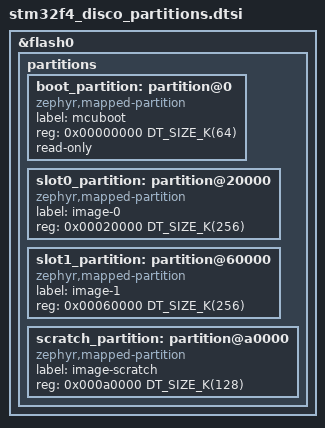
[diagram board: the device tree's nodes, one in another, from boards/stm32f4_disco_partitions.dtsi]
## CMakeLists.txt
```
# SPDX-License-Identifier: Apache-2.0

cmake_minimum_required(VERSION 3.20.0)

find_package(Zephyr REQUIRED HINTS $ENV{ZEPHYR_BASE})
project(mcumgr_update)

target_sources(app PRIVATE src/main.c)
```

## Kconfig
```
# SPDX-License-Identifier: Apache-2.0

mainmenu "MCUmgr update test application"

config APP_BLINK_MS
	int "LED blink half-period in ms"
	default 1000
	help
	  Each test image uses a different blink rate, so the running
	  version is visible on the board.

config APP_SIMULATE_BAD_IMAGE
	bool "Simulate a broken image (never confirm)"
	help
	  The self-test fails, so the image is never confirmed.
	  SWUpdate times out waiting for the confirmation, resets the MCU
	  and MCUboot reverts to the previous image.

source "Kconfig.zephyr"
```

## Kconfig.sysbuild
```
# SPDX-License-Identifier: Apache-2.0

# MCUboot mode per board. Both modes keep the rollback (test / confirm):
# - frdm_k64f: 4 KiB sectors, equal slots -> swap using move
# - stm32f4_disco: 128 KiB sectors -> swap using scratch, as the other
#   STM32F4 boards of Zephyr
choice MCUBOOT_MODE
	default MCUBOOT_MODE_SWAP_SCRATCH if "$(BOARD)" = "stm32f4_disco"
	default MCUBOOT_MODE_SWAP_USING_MOVE if "$(BOARD)" = "frdm_k64f"
endchoice

source "share/sysbuild/Kconfig"
```

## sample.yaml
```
sample:
  name: MCUmgr update test (SWUpdate mcumgr handler)
  description: Signed MCUboot application updated over SMP/UART by SWUpdate
common:
  sysbuild: true
  # no console output: tested with SWUpdate on the host, see README.md
  build_only: true
  platform_allow:
    - frdm_k64f
    - stm32f4_disco
  integration_platforms:
    - frdm_k64f
    - stm32f4_disco
  tags: mcumgr mcuboot dfu
tests:
  sample.mcumgr_update.v1: {}
  sample.mcumgr_update.v2:
    extra_args: EXTRA_CONF_FILE="v2.conf"
  sample.mcumgr_update.bad:
    extra_args: EXTRA_CONF_FILE="bad.conf"
```

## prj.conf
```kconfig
# GPIO for the status LED
CONFIG_GPIO=y

# MCUmgr core
CONFIG_NET_BUF=y
CONFIG_ZCBOR=y
CONFIG_CRC=y
CONFIG_BASE64=y
CONFIG_MCUMGR=y
CONFIG_SYSTEM_WORKQUEUE_STACK_SIZE=2304
CONFIG_MAIN_STACK_SIZE=2176

# Image management (upload, test, confirm) and OS group (reset)
CONFIG_FLASH=y
CONFIG_FLASH_MAP=y
CONFIG_STREAM_FLASH=y
CONFIG_IMG_MANAGER=y
CONFIG_MCUMGR_GRP_IMG=y
CONFIG_MCUMGR_GRP_OS=y

# Build an MCUboot compatible, signed image
CONFIG_BOOTLOADER_MCUBOOT=y

# SMP on its own UART transport, on the UART in zephyr,uart-mcumgr (board
# devicetree or boards/<board>.overlay). This UART carries only SMP frames:
# no shell, no console, no printk (MCUboot still prints its boot log, the
# host ignores it).
CONFIG_CONSOLE=y
CONFIG_UART_CONSOLE=n
CONFIG_PRINTK=n
CONFIG_BOOT_BANNER=n
CONFIG_LOG=n
CONFIG_SHELL=n
CONFIG_UART_MCUMGR=y
CONFIG_MCUMGR_TRANSPORT_UART=y
```

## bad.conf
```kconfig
# Broken image: boots but never confirms -> rollback test
CONFIG_APP_BLINK_MS=50
CONFIG_APP_SIMULATE_BAD_IMAGE=y
CONFIG_MCUBOOT_IMGTOOL_SIGN_VERSION="3.0.0+0"
```

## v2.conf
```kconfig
# Second image: fast blink, higher MCUboot version
CONFIG_APP_BLINK_MS=150
CONFIG_MCUBOOT_IMGTOOL_SIGN_VERSION="2.0.0+0"
```

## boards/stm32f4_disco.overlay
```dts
/*
 * SPDX-License-Identifier: Apache-2.0
 *
 * STM32F4DISCOVERY (STM32F407G-DISC1) + MikroElektronika STM32F4 Discovery
 * Shield (MIKROE-1481).
 *
 * SMP runs on USART2 (PA2 TX, PA3 RX), wired on the shield to its FT232RL
 * USB-UART (mini-B connector, /dev/ttyUSB0 on the host). The application
 * has no console: USART2 carries only SMP frames (and the MCUboot log).
 */

#include "stm32f4_disco_partitions.dtsi"

/ {
	chosen {
		zephyr,code-partition = &slot0_partition;
		zephyr,uart-mcumgr = &usart2;
	};
};
```

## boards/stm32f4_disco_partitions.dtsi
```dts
/*
 * SPDX-License-Identifier: Apache-2.0
 *
 * MCUboot flash layout for the STM32F407VG (1 MiB) of the STM32F4DISCOVERY,
 * used by the application and by MCUboot (see sysbuild.cmake).
 *
 * Sectors: 4 x 16 KiB, 1 x 64 KiB, 7 x 128 KiB. Both slots and the scratch
 * area are made of 128 KiB sectors (swap using scratch).
 *
 * zephyr,mapped-partition (Zephyr 4.4+): a fixed-partitions code partition
 * is deprecated.
 */

&flash0 {
	partitions {
		#address-cells = <1>;
		#size-cells = <1>;
		ranges;

		/* sectors 0-3 */
		boot_partition: partition@0 {
			compatible = "zephyr,mapped-partition";
			label = "mcuboot";
			reg = <0x00000000 DT_SIZE_K(64)>;
			read-only;
		};

		/* sector 4 (64 KiB) unused */

		/* sectors 5-6 */
		slot0_partition: partition@20000 {
			compatible = "zephyr,mapped-partition";
			label = "image-0";
			reg = <0x00020000 DT_SIZE_K(256)>;
		};

		/* sectors 7-8 */
		slot1_partition: partition@60000 {
			compatible = "zephyr,mapped-partition";
			label = "image-1";
			reg = <0x00060000 DT_SIZE_K(256)>;
		};

		/* sector 9 */
		scratch_partition: partition@a0000 {
			compatible = "zephyr,mapped-partition";
			label = "image-scratch";
			reg = <0x000a0000 DT_SIZE_K(128)>;
		};
	};
};
```

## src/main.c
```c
/*
 * SPDX-License-Identifier: Apache-2.0
 *
 * Test application for the SWUpdate "mcumgr" handler.
 *
 * - Exposes MCUmgr SMP (image + os groups) on the dedicated UART
 *   transport (uart0). The UART carries only SMP frames: no console,
 *   no shell, no printk.
 * - At boot, if MCUboot started this image in test mode, it runs a
 *   self-test and confirms the image. With CONFIG_APP_SIMULATE_BAD_IMAGE
 *   the self-test fails, the image is never confirmed and MCUboot
 *   reverts it at the next reset.
 * - The LED blink rate identifies the running build; the version is also
 *   reported by SMP (image state "version").
 */

#include <errno.h>
#include <zephyr/kernel.h>
#include <zephyr/drivers/gpio.h>
#include <zephyr/dfu/mcuboot.h>

static const struct gpio_dt_spec led = GPIO_DT_SPEC_GET(DT_ALIAS(led0), gpios);

static int self_test(void)
{
	if (IS_ENABLED(CONFIG_APP_SIMULATE_BAD_IMAGE)) {
		return -EIO;
	}

	if (!gpio_is_ready_dt(&led)) {
		return -ENODEV;
	}

	return 0;
}

int main(void)
{
	/* image started in test mode by MCUboot: confirm it if healthy */
	if (!boot_is_img_confirmed() && self_test() == 0) {
		(void)boot_write_img_confirmed();
	}

	if (!gpio_is_ready_dt(&led) ||
	    gpio_pin_configure_dt(&led, GPIO_OUTPUT_INACTIVE)) {
		return 0;
	}

	while (1) {
		gpio_pin_toggle_dt(&led);
		k_msleep(CONFIG_APP_BLINK_MS);
	}

	return 0;
}
```
